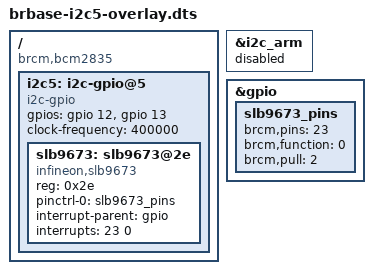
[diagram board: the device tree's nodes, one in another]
// Device tree overlay for https://kws-computer.de/produkte-2/bridgeth/base
// for details see ...

/dts-v1/;
/plugin/;

/ {
    compatible = "brcm,bcm2835";

    fragment@0 {
        target = <&i2c_arm>;
        __overlay__ {
            status = "disabled";
        };
    };

    fragment@1 {
        target-path = "/";
        __overlay__ {
            i2c5: i2c-gpio@5 {
                #address-cells = <1>;
                #size-cells = <0>;
                compatible = "i2c-gpio";
                gpios = <&gpio 12 6>, /* SDA GPIO_OPEN_DRAIN */
                        <&gpio 13 6>; /* CLK GPIO_OPEN_DRAIN */
                clock-frequency = <400000>;
                status = "okay";
            };
        };
    };

    fragment@2 {
        target = <&gpio>;
        __overlay__ {
            slb9673_pins: slb9673_pins {
                brcm,pins = <23>;
                brcm,function = <0>; // GPIO_IN
                brcm,pull = <2>; // Pull-up
            };
        };
    };

    fragment@3 {
        target = <&i2c5>;
        __overlay__ {
            #address-cells = <1>;
            #size-cells = <0>;

            slb9673: slb9673@2e {
                compatible = "infineon,slb9673", "tcg,tpm-tis-i2c";
                reg = <0x2e>;
                pinctrl-names = "default";
                pinctrl-0 = <&slb9673_pins>;
                interrupt-parent = <&gpio>;
                interrupts = <23 0>; // GPIO16, active-low
                status = "okay";
            };
        };
    };
};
